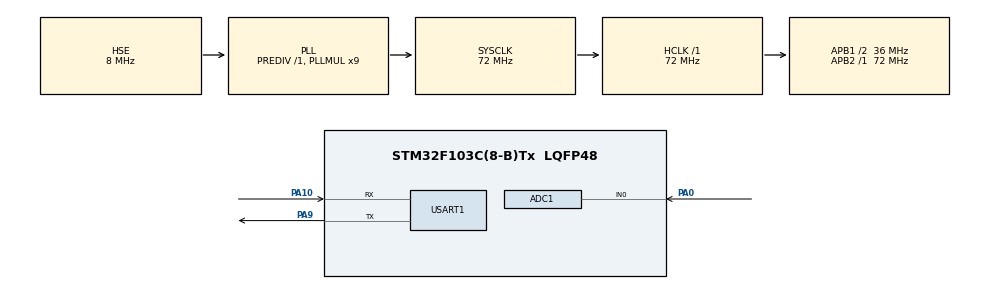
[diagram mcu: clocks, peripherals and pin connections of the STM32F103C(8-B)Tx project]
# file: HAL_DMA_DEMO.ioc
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ADC1.Channel-0\#ChannelRegularConversion=ADC_CHANNEL_0
ADC1.ContinuousConvMode=ENABLE
ADC1.NbrOfConversion=1
ADC1.NbrOfConversionFlag=1
ADC1.Rank-0\#ChannelRegularConversion=1
ADC1.SamplingTime-0\#ChannelRegularConversion=ADC_SAMPLETIME_1CYCLE_5
ADC1.master=1
Dma.MEMTOMEM.0.Direction=DMA_MEMORY_TO_MEMORY
Dma.MEMTOMEM.0.Instance=DMA1_Channel2
Dma.MEMTOMEM.0.MemDataAlignment=DMA_MDATAALIGN_BYTE
Dma.MEMTOMEM.0.MemInc=DMA_MINC_ENABLE
Dma.MEMTOMEM.0.Mode=DMA_NORMAL
Dma.MEMTOMEM.0.PeriphDataAlignment=DMA_PDATAALIGN_BYTE
Dma.MEMTOMEM.0.PeriphInc=DMA_PINC_ENABLE
Dma.MEMTOMEM.0.Priority=DMA_PRIORITY_LOW
Dma.Request0=MEMTOMEM
Dma.Request1=USART1_TX
Dma.USART1_TX.1.Direction=DMA_MEMORY_TO_PERIPH
Dma.USART1_TX.1.Instance=DMA1_Channel4
Dma.USART1_TX.1.MemDataAlignment=DMA_MDATAALIGN_BYTE
Dma.USART1_TX.1.MemInc=DMA_MINC_ENABLE
Dma.USART1_TX.1.Mode=DMA_CIRCULAR
Dma.USART1_TX.1.PeriphDataAlignment=DMA_PDATAALIGN_BYTE
Dma.USART1_TX.1.PeriphInc=DMA_PINC_DISABLE
Dma.USART1_TX.1.Priority=DMA_PRIORITY_LOW
Mcu.Family=STM32F1
Mcu.Name=STM32F103C(8-B)Tx
Mcu.Package=LQFP48
NVIC.ADC1_2_IRQn=true\:0\:0\:false\:false\:true\:true\:true
NVIC.DMA1_Channel4_IRQn=true\:0\:0\:false\:false\:true\:false\:true
NVIC.PriorityGroup=NVIC_PRIORITYGROUP_4
PA0-WKUP.Signal=ADCx_IN0
PA10.Mode=Asynchronous
PA10.Signal=USART1_RX
PA13.Mode=Serial_Wire
PA13.Signal=SYS_JTMS-SWDIO
PA14.Mode=Serial_Wire
PA14.Signal=SYS_JTCK-SWCLK
PA9.Mode=Asynchronous
PA9.Signal=USART1_TX
PC14-OSC32_IN.Mode=LSE-External-Oscillator
PC14-OSC32_IN.Signal=RCC_OSC32_IN
PC15-OSC32_OUT.Mode=LSE-External-Oscillator
PC15-OSC32_OUT.Signal=RCC_OSC32_OUT
PD0-OSC_IN.Mode=HSE-External-Oscillator
PD0-OSC_IN.Signal=RCC_OSC_IN
PD1-OSC_OUT.Mode=HSE-External-Oscillator
PD1-OSC_OUT.Signal=RCC_OSC_OUT
ProjectManager.HeapSize=0x200
ProjectManager.StackSize=0x400
ProjectManager.TargetToolchain=MDK-ARM V5.27
RCC.ADCPresc=RCC_ADCPCLK2_DIV6
RCC.AHBFreq_Value=72000000
RCC.APB1CLKDivider=RCC_HCLK_DIV2
RCC.APB1Freq_Value=36000000
RCC.APB1TimFreq_Value=72000000
RCC.APB2Freq_Value=72000000
RCC.APB2TimFreq_Value=72000000
RCC.HCLKFreq_Value=72000000
RCC.PLLMUL=RCC_PLL_MUL9
RCC.PLLSourceVirtual=RCC_PLLSOURCE_HSE
RCC.SYSCLKFreq_VALUE=72000000
RCC.SYSCLKSource=RCC_SYSCLKSOURCE_PLLCLK
RCC.USBFreq_Value=72000000
SH.ADCx_IN0.0=ADC1_IN0,IN0
USART1.VirtualMode=VM_ASYNC
board=custom

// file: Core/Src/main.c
/* USER CODE BEGIN Header */
/**
  ******************************************************************************
  * @file           : main.c
  * @brief          : Main program body
  ******************************************************************************
  * @attention
  *
  * <h2><center>&copy; Copyright (c) 2022 STMicroelectronics.
  * All rights reserved.</center></h2>
  *
  * This software component is licensed by ST under BSD 3-Clause license,
  * the "License"; You may not use this file except in compliance with the
  * License. You may obtain a copy of the License at:
  *                        opensource.org/licenses/BSD-3-Clause
  *
  ******************************************************************************
  */
/* USER CODE END Header */
#include "main.h"
#include "adc.h"
#include "dma.h"
#include "usart.h"
#include "gpio.h"

/* USER CODE BEGIN PV */

volatile uint8_t uart_tx_buf[] = {0, 1, 2, 3, 4, 5, 6, 7};

uint8_t src_value[16] = 	{12, 23, 34, 45, 56, 78, 90, 01,
													12, 23, 34, 45, 56, 78, 90, 01};

uint8_t dst_value[16];

__IO uint16_t ADC_ConvertedValue;
//uint32_t ADC_ConvertedValue;
/* USER CODE END PV */

void SystemClock_Config(void);

int main(void)
{

  /* MCU Configuration--------------------------------------------------------*/

  /* Reset of all peripherals, Initializes the Flash interface and the Systick. */
  HAL_Init();

  /* Configure the system clock */
  SystemClock_Config();

  /* Initialize all configured peripherals */
  MX_GPIO_Init();
  MX_DMA_Init();
  MX_USART1_UART_Init();
  MX_ADC1_Init();
  /* USER CODE BEGIN 2 */

	//DMA start
	HAL_DMA_Start(&hdma_memtomem_dma1_channel2, (uint32_t )src_value, (uint32_t )dst_value, 16);

	HAL_Delay(10);
	//start ADC conv it
	HAL_ADC_Start_IT(&hadc1);

	//DMA UART transmit continuous
	HAL_UART_Transmit_DMA(&huart1, (uint8_t*)uart_tx_buf, 8);

  /* USER CODE END 2 */

  /* Infinite loop */
  while (1)
  {
		for(uint8_t i=0; i<8; i++)
		{
			//change buff value
			uart_tx_buf[i] ++;
		}
  }
}

void SystemClock_Config(void)
{
  RCC_OscInitTypeDef RCC_OscInitStruct = {0};
  RCC_ClkInitTypeDef RCC_ClkInitStruct = {0};
  RCC_PeriphCLKInitTypeDef PeriphClkInit = {0};

  /** Initializes the RCC Oscillators according to the specified parameters
  * in the RCC_OscInitTypeDef structure.
  */
  RCC_OscInitStruct.OscillatorType = RCC_OSCILLATORTYPE_HSE;
  RCC_OscInitStruct.HSEState = RCC_HSE_ON;
  RCC_OscInitStruct.HSEPredivValue = RCC_HSE_PREDIV_DIV1;
  RCC_OscInitStruct.HSIState = RCC_HSI_ON;
  RCC_OscInitStruct.PLL.PLLState = RCC_PLL_ON;
  RCC_OscInitStruct.PLL.PLLSource = RCC_PLLSOURCE_HSE;
  RCC_OscInitStruct.PLL.PLLMUL = RCC_PLL_MUL9;
  if (HAL_RCC_OscConfig(&RCC_OscInitStruct) != HAL_OK)
  {
    Error_Handler();
  }
  /** Initializes the CPU, AHB and APB buses clocks
  */
  RCC_ClkInitStruct.ClockType = RCC_CLOCKTYPE_HCLK|RCC_CLOCKTYPE_SYSCLK
                              |RCC_CLOCKTYPE_PCLK1|RCC_CLOCKTYPE_PCLK2;
  RCC_ClkInitStruct.SYSCLKSource = RCC_SYSCLKSOURCE_PLLCLK;
  RCC_ClkInitStruct.AHBCLKDivider = RCC_SYSCLK_DIV1;
  RCC_ClkInitStruct.APB1CLKDivider = RCC_HCLK_DIV2;
  RCC_ClkInitStruct.APB2CLKDivider = RCC_HCLK_DIV1;

  if (HAL_RCC_ClockConfig(&RCC_ClkInitStruct, FLASH_LATENCY_2) != HAL_OK)
  {
    Error_Handler();
  }
  PeriphClkInit.PeriphClockSelection = RCC_PERIPHCLK_ADC;
  PeriphClkInit.AdcClockSelection = RCC_ADCPCLK2_DIV6;
  if (HAL_RCCEx_PeriphCLKConfig(&PeriphClkInit) != HAL_OK)
  {
    Error_Handler();
  }
}

void Error_Handler(void)
{
  __disable_irq();
  while (1)
  {
  }
}

/************************ (C) COPYRIGHT STMicroelectronics *****END OF FILE****/
